# M261_v1 register map
File version: 1.0
M261_v1 SVD file
Registers are 32-bit, read-write, reset 0x0 unless marked. A register's access mark holds for its fields unless they carry their own. Offsets are from the block's base; lines under a group give offsets from that group; [hi:lo] are bit positions; {n}, {i} and the like mark numbered series; 'fields as' and 'values as' point back to an identical list; <NAME> marks a mode.

## Memory map
0x40000000 SYS blocks up to offset 0x200 — SYS Register Map
0x40000200 CLK blocks up to offset 0xB8 — CLK Register Map
0x40000300 NMI size 0x8 — NMI Register Map
0x40004000 GPIO blocks up to offset 0xA00 — GPIO Register Map
0x40008000 PDMA0 blocks up to offset 0x530 — PDMA Register Map
0x40009000 USBH blocks up to offset 0x208 — USBH Register Map
0x4000C000 FMC blocks up to offset 0xE4 — FMC Register Map
0x4000D000 SDH0 blocks up to offset 0x840 — SDH Register Map
0x40010000 EBI blocks up to offset 0x28 — EBI Register Map
0x40018000 PDMA1 blocks up to offset 0x530 — PDMA Register Map
0x40031000 CRC size 0x10 — CRC Register Map
0x40032000 CRYPTO blocks up to offset 0xA58 — CRYPTO Register Map
0x40040000 WDT size 0xC — WDT Register Map
0x40040100 WWDT size 0x10 — WWDT Register Map
0x40041000 RTC blocks up to offset 0x148 — RTC Register Map
0x40043000 EADC blocks up to offset 0x11C — EADC Register Map
0x40045000 ACMP01 size 0x10 — ACMP Register Map
0x40047000 DAC blocks up to offset 0x58 — DAC Register Map
0x40048000 I2S blocks up to offset 0x28 — I2S Register Map
0x4004D000 OTG size 0x14 — OTG Register Map
0x40050000 TMR01 blocks up to offset 0x1A8 — TIMER Register Map
0x40051000 TMR23 blocks up to offset 0x1A8 — TIMER Register Map
0x40058000 EPWM0 blocks up to offset 0x350 — EPWM Register Map
0x40059000 EPWM1 blocks up to offset 0x350 — EPWM Register Map
0x4005A000 BPWM0 blocks up to offset 0x334 — BPWM Register Map
0x4005B000 BPWM1 blocks up to offset 0x334 — BPWM Register Map
0x40060000 QSPI0 blocks up to offset 0x34 — QSPI Register Map
0x40061000 SPI0 blocks up to offset 0x6C — SPI Register Map
0x40062000 SPI1 blocks up to offset 0x6C — SPI Register Map
0x40063000 SPI2 blocks up to offset 0x6C — SPI Register Map
0x40064000 SPI3 blocks up to offset 0x6C — SPI Register Map
0x40070000 UART0 size 0x4C — UART Register Map
0x40071000 UART1 size 0x4C — UART Register Map
0x40072000 UART2 blocks up to offset 0x4C — UART Register Map
0x40073000 UART3 blocks up to offset 0x4C — UART Register Map
0x40074000 UART4 blocks up to offset 0x4C — UART Register Map
0x40075000 UART5 blocks up to offset 0x4C — UART Register Map
0x40080000 I2C0 blocks up to offset 0x6C — I2C Register Map
0x40081000 I2C1 blocks up to offset 0x6C — I2C Register Map
0x40082000 I2C2 blocks up to offset 0x6C — I2C Register Map
0x40090000 SC0 blocks up to offset 0x50 — SC Register Map
0x40091000 SC1 blocks up to offset 0x50 — SC Register Map
0x40092000 SC2 blocks up to offset 0x50 — SC Register Map
0x400A0000 CAN blocks up to offset 0x170 — CAN Register Map
0x400B0000 QEI0 blocks up to offset 0x30 — QEI Register Map
0x400B1000 QEI1 blocks up to offset 0x30 — QEI Register Map
0x400B4000 ECAP0 size 0x20 — ECAP Register Map
0x400B5000 ECAP1 size 0x20 — ECAP Register Map
0x400B9000 TRNG blocks up to offset 0x10 — TRNG Register Map
0x400C0000 USBD blocks up to offset 0x5C0 — USBD Register Map
0x400D0000 UUART0 blocks up to offset 0x68 — UUARTUART Register Map
0x400D0000 USPI0 blocks up to offset 0x68 — USCISPI Register Map
0x400D0000 UI2C0 blocks up to offset 0x90 — UI2CI2C Register Map
0x400D1000 UUART1 blocks up to offset 0x68 — UUARTUART Register Map
0x400D1000 USPI1 blocks up to offset 0x68 — USCISPI Register Map
0x400D1000 UI2C1 blocks up to offset 0x90 — UI2CI2C Register Map
0xE000E000 SCS blocks up to offset 0xD28 — SYST_SCR Register Map
0xE000E100 NVIC blocks up to offset 0x368 — NVIC Register Map

## NVIC — NVIC Register Map
Base 0xE000E100
{0x0+4i} NVIC_ISER{i} (i=0..2) — IRQ{32i:02} ~ IRQ{32i+31} Set-Enable Control Register
  [31:0] SETENA — Interrupt Set Enable Bit. The NVIC_ISER0-NVIC_ISER3 registers enable interrupts, and show which interrupts are enabled. Write Operation:
    0=No effect. Interrupt Disabled; 1=Interrupt Enabled
0x0C NVIC_ISER3 — IRQ96 ~ IRQ101 Set-Enable Control Register
  fields as NVIC_ISER0
{0x80+4i} NVIC_ICER{i} (i=0..2) — IRQ{32i:02} ~ IRQ{32i+31} Clear-Enable Control Register
  [31:0] CALENA — Interrupt Clear Enable Bit. The NVIC_ICER0-NVIC_ICER3 registers disable interrupts, and show which interrupts are enabled. Write Operation:
    0=No effect. Interrupt Disabled; 1=Interrupt Disabled. Interrupt Enabled
0x8C NVIC_ICER3 — IRQ96 ~ IRQ101 Clear-Enable Control Register
  fields as NVIC_ICER0
{0x100+4i} NVIC_ISPR{i} (i=0..2) — IRQ{32i:02} ~ IRQ{32i+31} Set-Pending Control Register
  [31:0] SETPEND — Interrupt Set-pending. The NVIC_ISPR0-NVIC_ISPR3 registers force interrupts into the pending state, and show which interrupts are pending. Write Operation:
    0=No effect. Interrupt is not pending; 1=Changes interrupt state to pending. Interrupt is pending
0x10C NVIC_ISPR3 — IRQ96 ~ IRQ101 Set-Pending Control Register
  fields as NVIC_ISPR0
{0x180+4i} NVIC_ICPR{i} (i=0..2) — IRQ{32i:02} ~ IRQ{32i+31} Clear-Pending Control Register
  [31:0] CALPEND — Interrupt Clear-pending. The NVIC_ICPR0-NVIC_ICPR3 registers remove the pending state from interrupts, and show which interrupts are pending. Write Operation:
    0=No effect. Interrupt is not pending; 1=Removes pending state an interrupt. Interrupt is pending
0x18C NVIC_ICPR3 — IRQ96 ~ IRQ101 Clear-Pending Control Register
  fields as NVIC_ICPR0
{0x200+4i} NVIC_IABR{i} (i=0..2) — IRQ{32i:02} ~ IRQ{32i+31} Active Bit Register
  [31:0] ACTIVE — Interrupt Active Flags. The NVIC_IABR0-NVIC_IABR3 registers indicate which interrupts are active.
    0=interrupt not active; 1=interrupt active
0x20C NVIC_IABR3 — IRQ96 ~ IRQ101 Active Bit Register
  fields as NVIC_IABR0
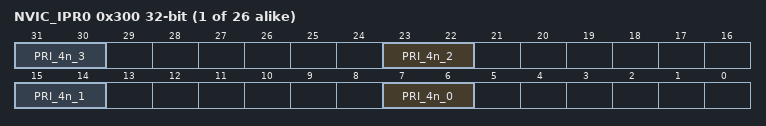
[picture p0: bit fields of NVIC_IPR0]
{0x300+4i} NVIC_IPR{i} (i=0..25) — IRQ0 ~ IRQ101 Priority Control Register
  [8n+7:8n+6] PRI_4n_{n} (n=0..3) — Priority of IRQ_4n+{n} '0' denotes the highest priority and '3' denotes the lowest priority.
